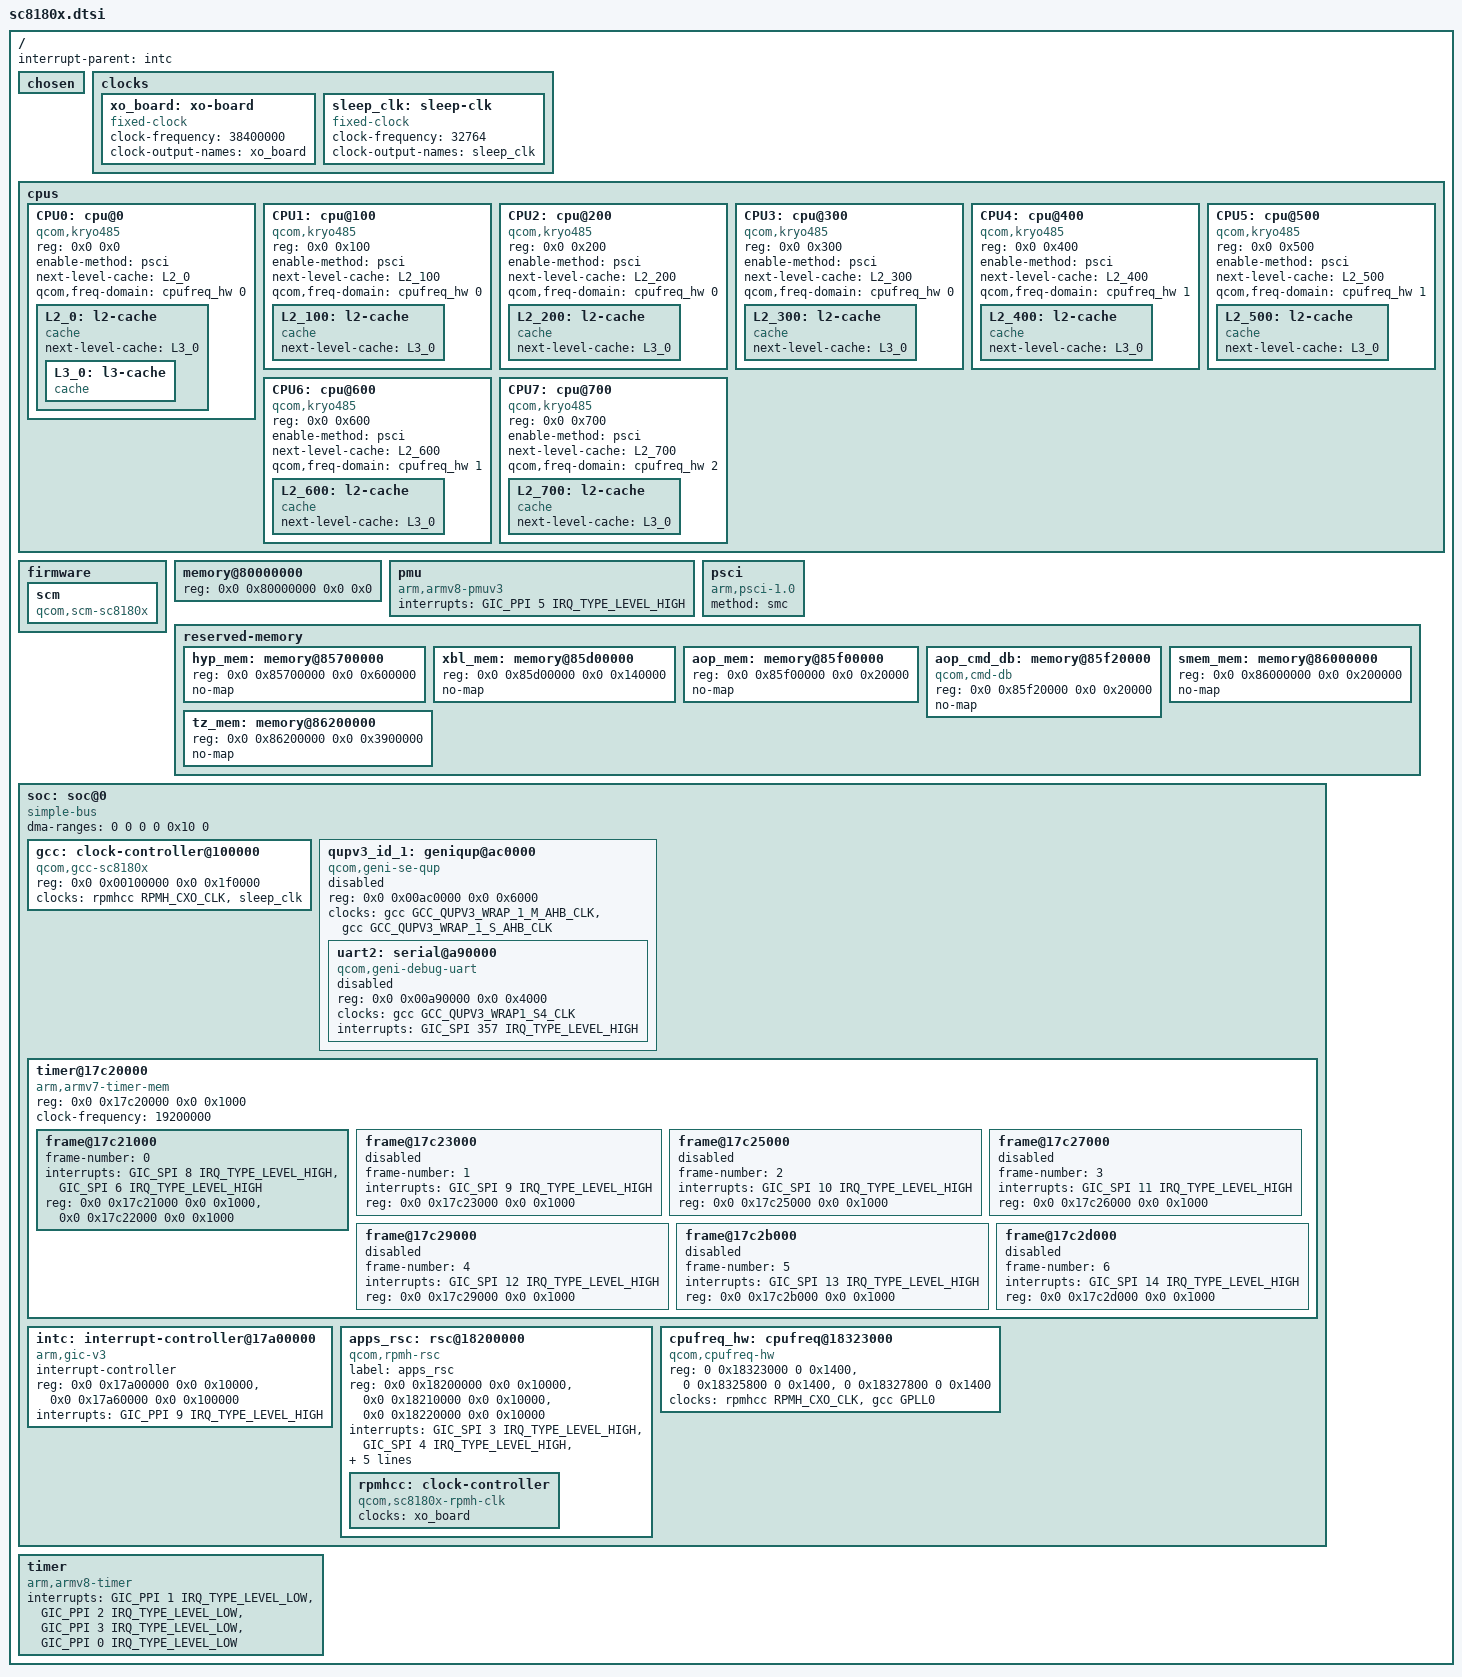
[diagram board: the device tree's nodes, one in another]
// SPDX-License-Identifier: BSD-3-Clause
/*
 * Copyright (c) 2017-2019, The Linux Foundation. All rights reserved.
 * Copyright (c) 2020, Linaro Limited
 */

#include <dt-bindings/interrupt-controller/arm-gic.h>
#include <dt-bindings/power/qcom-aoss-qmp.h>
#include <dt-bindings/power/qcom-rpmpd.h>
#include <dt-bindings/soc/qcom,rpmh-rsc.h>
#include <dt-bindings/clock/qcom,rpmh.h>
#include <dt-bindings/clock/qcom,gcc-sc8180x.h>
#include <dt-bindings/thermal/thermal.h>

/ {
	interrupt-parent = <&intc>;

	#address-cells = <2>;
	#size-cells = <2>;

	chosen { };

	clocks {
		xo_board: xo-board {
			compatible = "fixed-clock";
			#clock-cells = <0>;
			clock-frequency = <38400000>;
			clock-output-names = "xo_board";
		};

		sleep_clk: sleep-clk {
			compatible = "fixed-clock";
			#clock-cells = <0>;
			clock-frequency = <32764>;
			clock-output-names = "sleep_clk";
		};
	};

	cpus {
		#address-cells = <2>;
		#size-cells = <0>;

		CPU0: cpu@0 {
			device_type = "cpu";
			compatible = "qcom,kryo485";
			reg = <0x0 0x0>;
			enable-method = "psci";
			next-level-cache = <&L2_0>;
			qcom,freq-domain = <&cpufreq_hw 0>;
			#cooling-cells = <2>;
			L2_0: l2-cache {
				compatible = "cache";
				next-level-cache = <&L3_0>;
				L3_0: l3-cache {
				      compatible = "cache";
				};
			};
		};

		CPU1: cpu@100 {
			device_type = "cpu";
			compatible = "qcom,kryo485";
			reg = <0x0 0x100>;
			enable-method = "psci";
			next-level-cache = <&L2_100>;
			qcom,freq-domain = <&cpufreq_hw 0>;
			#cooling-cells = <2>;
			L2_100: l2-cache {
				compatible = "cache";
				next-level-cache = <&L3_0>;
			};

		};

		CPU2: cpu@200 {
			device_type = "cpu";
			compatible = "qcom,kryo485";
			reg = <0x0 0x200>;
			enable-method = "psci";
			next-level-cache = <&L2_200>;
			qcom,freq-domain = <&cpufreq_hw 0>;
			#cooling-cells = <2>;
			L2_200: l2-cache {
				compatible = "cache";
				next-level-cache = <&L3_0>;
			};
		};

		CPU3: cpu@300 {
			device_type = "cpu";
			compatible = "qcom,kryo485";
			reg = <0x0 0x300>;
			enable-method = "psci";
			next-level-cache = <&L2_300>;
			qcom,freq-domain = <&cpufreq_hw 0>;
			#cooling-cells = <2>;
			L2_300: l2-cache {
				compatible = "cache";
				next-level-cache = <&L3_0>;
			};
		};

		CPU4: cpu@400 {
			device_type = "cpu";
			compatible = "qcom,kryo485";
			reg = <0x0 0x400>;
			enable-method = "psci";
			next-level-cache = <&L2_400>;
			qcom,freq-domain = <&cpufreq_hw 1>;
			#cooling-cells = <2>;
			L2_400: l2-cache {
				compatible = "cache";
				next-level-cache = <&L3_0>;
			};
		};

		CPU5: cpu@500 {
			device_type = "cpu";
			compatible = "qcom,kryo485";
			reg = <0x0 0x500>;
			enable-method = "psci";
			next-level-cache = <&L2_500>;
			qcom,freq-domain = <&cpufreq_hw 1>;
			#cooling-cells = <2>;
			L2_500: l2-cache {
				compatible = "cache";
				next-level-cache = <&L3_0>;
			};
		};

		CPU6: cpu@600 {
			device_type = "cpu";
			compatible = "qcom,kryo485";
			reg = <0x0 0x600>;
			enable-method = "psci";
			next-level-cache = <&L2_600>;
			qcom,freq-domain = <&cpufreq_hw 1>;
			#cooling-cells = <2>;
			L2_600: l2-cache {
				compatible = "cache";
				next-level-cache = <&L3_0>;
			};
		};

		CPU7: cpu@700 {
			device_type = "cpu";
			compatible = "qcom,kryo485";
			reg = <0x0 0x700>;
			enable-method = "psci";
			next-level-cache = <&L2_700>;
			qcom,freq-domain = <&cpufreq_hw 2>;
			#cooling-cells = <2>;
			L2_700: l2-cache {
				compatible = "cache";
				next-level-cache = <&L3_0>;
			};
		};
	};

	firmware {
		scm: scm {
			compatible = "qcom,scm-sc8180x", "qcom,scm";
			#reset-cells = <1>;
		};
	};

	memory@80000000 {
		device_type = "memory";
		/* We expect the bootloader to fill in the size */
		reg = <0x0 0x80000000 0x0 0x0>;
	};

	pmu {
		compatible = "arm,armv8-pmuv3";
		interrupts = <GIC_PPI 5 IRQ_TYPE_LEVEL_HIGH>;
	};

	psci {
		compatible = "arm,psci-1.0";
		method = "smc";
	};

	reserved-memory {
		#address-cells = <2>;
		#size-cells = <2>;
		ranges;

		hyp_mem: memory@85700000 {
			reg = <0x0 0x85700000 0x0 0x600000>;
			no-map;
		};

		xbl_mem: memory@85d00000 {
			reg = <0x0 0x85d00000 0x0 0x140000>;
			no-map;
		};

		aop_mem: memory@85f00000 {
			reg = <0x0 0x85f00000 0x0 0x20000>;
			no-map;
		};

		aop_cmd_db: memory@85f20000 {
			compatible = "qcom,cmd-db";
			reg = <0x0 0x85f20000 0x0 0x20000>;
			no-map;
		};

		smem_mem: memory@86000000 {
			reg = <0x0 0x86000000 0x0 0x200000>;
			no-map;
		};

		tz_mem: memory@86200000 {
			reg = <0x0 0x86200000 0x0 0x3900000>;
			no-map;
		};
	};

	soc: soc@0 {
		#address-cells = <2>;
		#size-cells = <2>;
		ranges = <0 0 0 0 0x10 0>;
		dma-ranges = <0 0 0 0 0x10 0>;
		compatible = "simple-bus";

		gcc: clock-controller@100000 {
			compatible = "qcom,gcc-sc8180x";
			reg = <0x0 0x00100000 0x0 0x1f0000>;
			#clock-cells = <1>;
			#reset-cells = <1>;
			#power-domain-cells = <1>;
			clock-names = "bi_tcxo",
				      "sleep_clk";
			clocks = <&rpmhcc RPMH_CXO_CLK>,
				 <&sleep_clk>;
		};

		qupv3_id_1: geniqup@ac0000 {
			compatible = "qcom,geni-se-qup";
			reg = <0x0 0x00ac0000 0x0 0x6000>;
			clock-names = "m-ahb", "s-ahb";
			clocks = <&gcc GCC_QUPV3_WRAP_1_M_AHB_CLK>,
				 <&gcc GCC_QUPV3_WRAP_1_S_AHB_CLK>;
			#address-cells = <2>;
			#size-cells = <2>;
			ranges;
			status = "disabled";

			uart2: serial@a90000 {
				compatible = "qcom,geni-debug-uart";
				reg = <0x0 0x00a90000 0x0 0x4000>;
				clock-names = "se";
				clocks = <&gcc GCC_QUPV3_WRAP1_S4_CLK>;
				interrupts = <GIC_SPI 357 IRQ_TYPE_LEVEL_HIGH>;
				status = "disabled";
			};
		};

		timer@17c20000 {
			#address-cells = <2>;
			#size-cells = <2>;
			ranges;
			compatible = "arm,armv7-timer-mem";
			reg = <0x0 0x17c20000 0x0 0x1000>;
			clock-frequency = <19200000>;

			frame@17c21000{
				frame-number = <0>;
				interrupts = <GIC_SPI 8 IRQ_TYPE_LEVEL_HIGH>,
					     <GIC_SPI 6 IRQ_TYPE_LEVEL_HIGH>;
				reg = <0x0 0x17c21000 0x0 0x1000>,
				      <0x0 0x17c22000 0x0 0x1000>;
			};

			frame@17c23000 {
				frame-number = <1>;
				interrupts = <GIC_SPI 9 IRQ_TYPE_LEVEL_HIGH>;
				reg = <0x0 0x17c23000 0x0 0x1000>;
				status = "disabled";
			};

			frame@17c25000 {
				frame-number = <2>;
				interrupts = <GIC_SPI 10 IRQ_TYPE_LEVEL_HIGH>;
				reg = <0x0 0x17c25000 0x0 0x1000>;
				status = "disabled";
			};

			frame@17c27000 {
				frame-number = <3>;
				interrupts = <GIC_SPI 11 IRQ_TYPE_LEVEL_HIGH>;
				reg = <0x0 0x17c26000 0x0 0x1000>;
				status = "disabled";
			};

			frame@17c29000 {
				frame-number = <4>;
				interrupts = <GIC_SPI 12 IRQ_TYPE_LEVEL_HIGH>;
				reg = <0x0 0x17c29000 0x0 0x1000>;
				status = "disabled";
			};

			frame@17c2b000 {
				frame-number = <5>;
				interrupts = <GIC_SPI 13 IRQ_TYPE_LEVEL_HIGH>;
				reg = <0x0 0x17c2b000 0x0 0x1000>;
				status = "disabled";
			};

			frame@17c2d000 {
				frame-number = <6>;
				interrupts = <GIC_SPI 14 IRQ_TYPE_LEVEL_HIGH>;
				reg = <0x0 0x17c2d000 0x0 0x1000>;
				status = "disabled";
			};
		};

		intc: interrupt-controller@17a00000 {
			compatible = "arm,gic-v3";
			interrupt-controller;
			#interrupt-cells = <3>;
			reg = <0x0 0x17a00000 0x0 0x10000>,	/* GICD */
			      <0x0 0x17a60000 0x0 0x100000>;	/* GICR * 8 */
			interrupts = <GIC_PPI 9 IRQ_TYPE_LEVEL_HIGH>;
		};

		apps_rsc: rsc@18200000 {
			label = "apps_rsc";
			compatible = "qcom,rpmh-rsc";
			reg = <0x0 0x18200000 0x0 0x10000>,
			      <0x0 0x18210000 0x0 0x10000>,
			      <0x0 0x18220000 0x0 0x10000>;
			reg-names = "drv-0", "drv-1", "drv-2";
			interrupts = <GIC_SPI 3 IRQ_TYPE_LEVEL_HIGH>,
				     <GIC_SPI 4 IRQ_TYPE_LEVEL_HIGH>,
				     <GIC_SPI 5 IRQ_TYPE_LEVEL_HIGH>;
			qcom,tcs-offset = <0xd00>;
			qcom,drv-id = <2>;
			qcom,tcs-config = <ACTIVE_TCS  2>,
					  <SLEEP_TCS   1>,
					  <WAKE_TCS    1>,
					  <CONTROL_TCS 0>;

			rpmhcc: clock-controller {
				compatible = "qcom,sc8180x-rpmh-clk";
				#clock-cells = <1>;
				clock-names = "xo";
				clocks = <&xo_board>;
			};
		};

		cpufreq_hw: cpufreq@18323000 {
			compatible = "qcom,cpufreq-hw";
			reg = <0 0x18323000 0 0x1400>, <0 0x18325800 0 0x1400>,
			      <0 0x18327800 0 0x1400>;
			reg-names = "freq-domain0", "freq-domain1",
				    "freq-domain2";

			clocks = <&rpmhcc RPMH_CXO_CLK>, <&gcc GPLL0>;
			clock-names = "xo", "alternate";

			#freq-domain-cells = <1>;
		};
	};

	timer {
		compatible = "arm,armv8-timer";
		interrupts = <GIC_PPI 1 IRQ_TYPE_LEVEL_LOW>,
			     <GIC_PPI 2 IRQ_TYPE_LEVEL_LOW>,
			     <GIC_PPI 3 IRQ_TYPE_LEVEL_LOW>,
			     <GIC_PPI 0 IRQ_TYPE_LEVEL_LOW>;
	};
};
